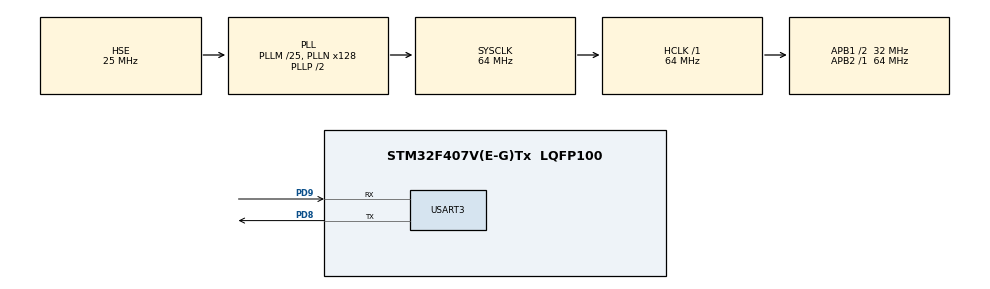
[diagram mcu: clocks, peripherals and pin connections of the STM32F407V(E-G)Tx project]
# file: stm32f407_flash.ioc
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Mcu.Family=STM32F4
Mcu.Name=STM32F407V(E-G)Tx
Mcu.Package=LQFP100
NVIC.PriorityGroup=NVIC_PRIORITYGROUP_4
NVIC.USART3_IRQn=true\:0\:0\:false\:false\:true\:true\:true\:true
PC14-OSC32_IN.Mode=LSE-External-Oscillator
PC14-OSC32_IN.Signal=RCC_OSC32_IN
PC15-OSC32_OUT.Mode=LSE-External-Oscillator
PC15-OSC32_OUT.Signal=RCC_OSC32_OUT
PD8.Mode=Asynchronous
PD8.Signal=USART3_TX
PD9.Mode=Asynchronous
PD9.Signal=USART3_RX
PH0-OSC_IN.Mode=HSE-External-Oscillator
PH0-OSC_IN.Signal=RCC_OSC_IN
PH1-OSC_OUT.Mode=HSE-External-Oscillator
PH1-OSC_OUT.Signal=RCC_OSC_OUT
ProjectManager.HeapSize=0x200
ProjectManager.StackSize=0x400
ProjectManager.TargetToolchain=STM32CubeIDE
RCC.48MHZClocksFreq_Value=32000000
RCC.AHBFreq_Value=64000000
RCC.APB1CLKDivider=RCC_HCLK_DIV2
RCC.APB1Freq_Value=32000000
RCC.APB1TimFreq_Value=64000000
RCC.APB2Freq_Value=64000000
RCC.APB2TimFreq_Value=64000000
RCC.CortexFreq_Value=64000000
RCC.HCLKFreq_Value=64000000
RCC.HSE_VALUE=25000000
RCC.HSI_VALUE=16000000
RCC.PLLM=25
RCC.PLLN=128
RCC.PLLSourceVirtual=RCC_PLLSOURCE_HSE
RCC.SYSCLKFreq_VALUE=64000000
RCC.SYSCLKSource=RCC_SYSCLKSOURCE_PLLCLK
RCC.VCOOutputFreq_Value=128000000
USART3.VirtualMode=VM_ASYNC
board=custom

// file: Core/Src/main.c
/* USER CODE BEGIN Header */
/**
  ******************************************************************************
  * @file           : main.c
  * @brief          : Main program body
  ******************************************************************************
  * @attention
  *
  * Copyright (c) 2025 STMicroelectronics.
  * All rights reserved.
  *
  * This software is licensed under terms that can be found in the LICENSE file
  * in the root directory of this software component.
  * If no LICENSE file comes with this software, it is provided AS-IS.
  *
  ******************************************************************************
  */
/* USER CODE END Header */
#include "main.h"
#include "usart.h"
#include "gpio.h"

/* USER CODE BEGIN Includes */
#include "ee.h"
/* USER CODE END Includes */

void SystemClock_Config(void);

/* USER CODE BEGIN 0 */
//https://www.waveshare.com/wiki/STM32CubeMX_Tutorial_Series:_USART
#ifdef __GNUC__
  /* With GCC/RAISONANCE, small printf (option LD Linker->Libraries->Small printf
     set to 'Yes') calls __io_putchar() */
  #define PUTCHAR_PROTOTYPE int __io_putchar(int ch)
#else
  #define PUTCHAR_PROTOTYPE int fputc(int ch, FILE *f)
#endif /* __GNUC__ */
/**
  * @brief  Retargets the C library printf function to the USART.
  * @param  None
  * @retval None
  */
PUTCHAR_PROTOTYPE
{
  /* Place your implementation of fputc here */
  /* e.g. write a character to the EVAL_COM1 and Loop until the end of transmission */
  HAL_UART_Transmit(&huart3, (uint8_t *)&ch, 1, 0xFFFF);

  return ch;
}
/* USER CODE END 0 */

int main(void)
{

  /* MCU Configuration--------------------------------------------------------*/

  /* Reset of all peripherals, Initializes the Flash interface and the Systick. */
  HAL_Init();

  /* Configure the system clock */
  SystemClock_Config();

  /* Initialize all configured peripherals */
  MX_GPIO_Init();
  MX_USART3_UART_Init();
  /* USER CODE BEGIN 2 */

  printf("\n\r !UART Printf Example: retarget the C library printf function to the UART\n\r");
    flash_memory_init();
  // Prepare data to write
    FlashDataUnion dataToWrite;
    //dataToWrite.dataStruct = (FlashDataStruct){0x03, 0x04, 0x05, 0x06};
    dataToWrite.dataStruct.byte1 = 0x06;
    dataToWrite.dataStruct.byte2 = 0x05;
    dataToWrite.dataStruct.byte3 = 0x04;
    dataToWrite.dataStruct.byte4 = 0x03;
    dataToWrite.dataStruct.byte_byte_byte_byte = 0x12345678;

    // Write data to flash
    write_flash_data(&dataToWrite);

    // Read data from flash to verify
    FlashDataUnion dataRead;
    read_flash_data(&dataRead);
    //printf("\n\rCUR_VALUE: %u\n\r", dataRead.dataStruct.byte_byte_byte_byte);
    print_flash_data(&dataRead);
  /* USER CODE END 2 */

  /* Infinite loop */
  while (1)
  {

  }
}

void SystemClock_Config(void)
{
  RCC_OscInitTypeDef RCC_OscInitStruct = {0};
  RCC_ClkInitTypeDef RCC_ClkInitStruct = {0};

  /** Configure the main internal regulator output voltage
  */
  __HAL_RCC_PWR_CLK_ENABLE();
  __HAL_PWR_VOLTAGESCALING_CONFIG(PWR_REGULATOR_VOLTAGE_SCALE1);

  /** Initializes the RCC Oscillators according to the specified parameters
  * in the RCC_OscInitTypeDef structure.
  */
  RCC_OscInitStruct.OscillatorType = RCC_OSCILLATORTYPE_HSE;
  RCC_OscInitStruct.HSEState = RCC_HSE_ON;
  RCC_OscInitStruct.PLL.PLLState = RCC_PLL_ON;
  RCC_OscInitStruct.PLL.PLLSource = RCC_PLLSOURCE_HSE;
  RCC_OscInitStruct.PLL.PLLM = 25;
  RCC_OscInitStruct.PLL.PLLN = 128;
  RCC_OscInitStruct.PLL.PLLP = RCC_PLLP_DIV2;
  RCC_OscInitStruct.PLL.PLLQ = 4;
  if (HAL_RCC_OscConfig(&RCC_OscInitStruct) != HAL_OK)
  {
    Error_Handler();
  }

  /** Initializes the CPU, AHB and APB buses clocks
  */
  RCC_ClkInitStruct.ClockType = RCC_CLOCKTYPE_HCLK|RCC_CLOCKTYPE_SYSCLK
                              |RCC_CLOCKTYPE_PCLK1|RCC_CLOCKTYPE_PCLK2;
  RCC_ClkInitStruct.SYSCLKSource = RCC_SYSCLKSOURCE_PLLCLK;
  RCC_ClkInitStruct.AHBCLKDivider = RCC_SYSCLK_DIV1;
  RCC_ClkInitStruct.APB1CLKDivider = RCC_HCLK_DIV2;
  RCC_ClkInitStruct.APB2CLKDivider = RCC_HCLK_DIV1;

  if (HAL_RCC_ClockConfig(&RCC_ClkInitStruct, FLASH_LATENCY_2) != HAL_OK)
  {
    Error_Handler();
  }
}

void Error_Handler(void)
{
  __disable_irq();
  while (1)
  {
  }
}
